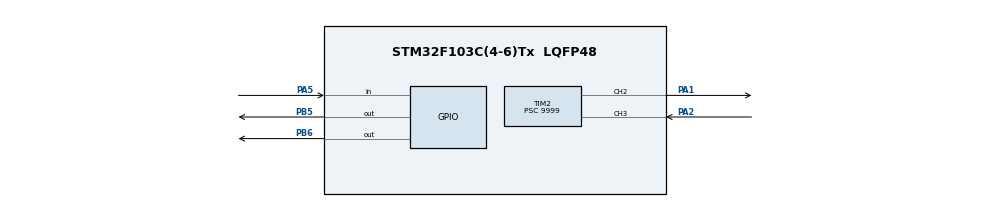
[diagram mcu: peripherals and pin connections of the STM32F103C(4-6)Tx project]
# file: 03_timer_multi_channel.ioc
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Mcu.Family=STM32F1
Mcu.Name=STM32F103C(4-6)Tx
Mcu.Package=LQFP48
NVIC.PriorityGroup=NVIC_PRIORITYGROUP_4
NVIC.TIM2_IRQn=true\:0\:0\:false\:false\:true\:true\:true\:true
PA1.Signal=S_TIM2_CH2
PA13.Mode=Serial_Wire
PA13.Signal=SYS_JTMS-SWDIO
PA14.Mode=Serial_Wire
PA14.Signal=SYS_JTCK-SWCLK
PA2.Signal=S_TIM2_CH3
PA5.Signal=GPIO_Input
PB5.Signal=GPIO_Output
PB6.Signal=GPIO_Output
ProjectManager.HeapSize=0x200
ProjectManager.StackSize=0x400
ProjectManager.TargetToolchain=STM32CubeIDE
RCC.APB1Freq_Value=8000000
RCC.APB2Freq_Value=8000000
SH.S_TIM2_CH2.0=TIM2_CH2,Output Compare2 CH2
SH.S_TIM2_CH3.0=TIM2_CH3,Input_Capture3_from_TI3
TIM2.Channel-Input_Capture3_from_TI3=TIM_CHANNEL_3
TIM2.Channel-Output\ Compare1\ No\ Output=TIM_CHANNEL_1
TIM2.Channel-Output\ Compare2\ CH2=TIM_CHANNEL_2
TIM2.OC2Preload=DISABLE
TIM2.OCMode_2=TIM_OCMODE_TOGGLE
TIM2.Prescaler=9999
TIM2.Pulse-Output\ Compare2\ CH2=400
VP_TIM2_VS_ClockSourceINT.Mode=Internal
VP_TIM2_VS_no_output1.Mode=Output Compare1 No Output
board=custom

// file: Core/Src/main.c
/* USER CODE BEGIN Header */
/**
  ******************************************************************************
  * @file           : main.c
  * @brief          : Main program body
  ******************************************************************************
  */
/* USER CODE END Header */
#include "main.h"

TIM_HandleTypeDef htim2;

void SystemClock_Config(void);
static void MX_GPIO_Init(void);
static void MX_TIM2_Init(void);

int main(void)
{

  /* MCU Configuration--------------------------------------------------------*/

  /* Reset of all peripherals, Initializes the Flash interface and the Systick. */
  HAL_Init();

  /* Configure the system clock */
  SystemClock_Config();

  /* Initialize all configured peripherals */
  MX_GPIO_Init();
  MX_TIM2_Init();
  /* USER CODE BEGIN 2 */
  HAL_TIM_OC_Start_IT(&htim2, TIM_CHANNEL_1);
  HAL_TIM_OC_Start_IT(&htim2, TIM_CHANNEL_2);

  /* USER CODE END 2 */

  /* Infinite loop */
  while (1)
  {

  }
}

void SystemClock_Config(void)
{
  RCC_OscInitTypeDef RCC_OscInitStruct = {0};
  RCC_ClkInitTypeDef RCC_ClkInitStruct = {0};

  /** Initializes the RCC Oscillators according to the specified parameters
  * in the RCC_OscInitTypeDef structure.
  */
  RCC_OscInitStruct.OscillatorType = RCC_OSCILLATORTYPE_HSI;
  RCC_OscInitStruct.HSIState = RCC_HSI_ON;
  RCC_OscInitStruct.HSICalibrationValue = RCC_HSICALIBRATION_DEFAULT;
  RCC_OscInitStruct.PLL.PLLState = RCC_PLL_NONE;
  if (HAL_RCC_OscConfig(&RCC_OscInitStruct) != HAL_OK)
  {
    Error_Handler();
  }

  /** Initializes the CPU, AHB and APB buses clocks
  */
  RCC_ClkInitStruct.ClockType = RCC_CLOCKTYPE_HCLK|RCC_CLOCKTYPE_SYSCLK
                              |RCC_CLOCKTYPE_PCLK1|RCC_CLOCKTYPE_PCLK2;
  RCC_ClkInitStruct.SYSCLKSource = RCC_SYSCLKSOURCE_HSI;
  RCC_ClkInitStruct.AHBCLKDivider = RCC_SYSCLK_DIV1;
  RCC_ClkInitStruct.APB1CLKDivider = RCC_HCLK_DIV1;
  RCC_ClkInitStruct.APB2CLKDivider = RCC_HCLK_DIV1;

  if (HAL_RCC_ClockConfig(&RCC_ClkInitStruct, FLASH_LATENCY_0) != HAL_OK)
  {
    Error_Handler();
  }
}

static void MX_TIM2_Init(void)
{

  TIM_ClockConfigTypeDef sClockSourceConfig = {0};
  TIM_MasterConfigTypeDef sMasterConfig = {0};
  TIM_OC_InitTypeDef sConfigOC = {0};
  TIM_IC_InitTypeDef sConfigIC = {0};

  htim2.Instance = TIM2;
  htim2.Init.Prescaler = 9999;
  htim2.Init.CounterMode = TIM_COUNTERMODE_UP;
  htim2.Init.Period = 799;
  htim2.Init.ClockDivision = TIM_CLOCKDIVISION_DIV1;
  htim2.Init.AutoReloadPreload = TIM_AUTORELOAD_PRELOAD_DISABLE;
  if (HAL_TIM_Base_Init(&htim2) != HAL_OK)
  {
    Error_Handler();
  }
  sClockSourceConfig.ClockSource = TIM_CLOCKSOURCE_INTERNAL;
  if (HAL_TIM_ConfigClockSource(&htim2, &sClockSourceConfig) != HAL_OK)
  {
    Error_Handler();
  }
  if (HAL_TIM_OC_Init(&htim2) != HAL_OK)
  {
    Error_Handler();
  }
  if (HAL_TIM_IC_Init(&htim2) != HAL_OK)
  {
    Error_Handler();
  }
  sMasterConfig.MasterOutputTrigger = TIM_TRGO_RESET;
  sMasterConfig.MasterSlaveMode = TIM_MASTERSLAVEMODE_DISABLE;
  if (HAL_TIMEx_MasterConfigSynchronization(&htim2, &sMasterConfig) != HAL_OK)
  {
    Error_Handler();
  }
  sConfigOC.OCMode = TIM_OCMODE_TIMING;
  sConfigOC.Pulse = 300;
  sConfigOC.OCPolarity = TIM_OCPOLARITY_HIGH;
  sConfigOC.OCFastMode = TIM_OCFAST_DISABLE;
  if (HAL_TIM_OC_ConfigChannel(&htim2, &sConfigOC, TIM_CHANNEL_1) != HAL_OK)
  {
    Error_Handler();
  }
  sConfigOC.OCMode = TIM_OCMODE_TOGGLE;
  sConfigOC.Pulse = 400;
  if (HAL_TIM_OC_ConfigChannel(&htim2, &sConfigOC, TIM_CHANNEL_2) != HAL_OK)
  {
    Error_Handler();
  }
  sConfigIC.ICPolarity = TIM_INPUTCHANNELPOLARITY_RISING;
  sConfigIC.ICSelection = TIM_ICSELECTION_DIRECTTI;
  sConfigIC.ICPrescaler = TIM_ICPSC_DIV1;
  sConfigIC.ICFilter = 0;
  if (HAL_TIM_IC_ConfigChannel(&htim2, &sConfigIC, TIM_CHANNEL_3) != HAL_OK)
  {
    Error_Handler();
  }
  HAL_TIM_MspPostInit(&htim2);

}

static void MX_GPIO_Init(void)
{
  GPIO_InitTypeDef GPIO_InitStruct = {0};

  /* GPIO Ports Clock Enable */
  __HAL_RCC_GPIOA_CLK_ENABLE();
  __HAL_RCC_GPIOB_CLK_ENABLE();

  /*Configure GPIO pin Output Level */
  HAL_GPIO_WritePin(GPIOB, GPIO_PIN_5|GPIO_PIN_6, GPIO_PIN_RESET);

  /*Configure GPIO pin : PA5 */
  GPIO_InitStruct.Pin = GPIO_PIN_5;
  GPIO_InitStruct.Mode = GPIO_MODE_INPUT;
  GPIO_InitStruct.Pull = GPIO_NOPULL;
  HAL_GPIO_Init(GPIOA, &GPIO_InitStruct);

  /*Configure GPIO pins : PB5 PB6 */
  GPIO_InitStruct.Pin = GPIO_PIN_5|GPIO_PIN_6;
  GPIO_InitStruct.Mode = GPIO_MODE_OUTPUT_PP;
  GPIO_InitStruct.Pull = GPIO_NOPULL;
  GPIO_InitStruct.Speed = GPIO_SPEED_FREQ_LOW;
  HAL_GPIO_Init(GPIOB, &GPIO_InitStruct);

}

void Error_Handler(void)
{
  __disable_irq();
  while (1)
  {
  }
}

void HAL_TIM_OC_DelayElapsedCallback(TIM_HandleTypeDef *htim)
{
    if (htim->Instance == TIM2)
    {
        if (htim->Channel == HAL_TIM_ACTIVE_CHANNEL_1)
        {
            HAL_GPIO_TogglePin(GPIOB, GPIO_PIN_6);
        }

        if (htim->Channel == HAL_TIM_ACTIVE_CHANNEL_2)
        {

        }
    }
}
